# IVA2_CM register map
Vendor: Texas Instruments
Peripheral module from a debugger description file (folder omap34xx).
Registers are 32-bit, access per field, reset 0x0 unless marked. A register's access mark holds for its fields unless they carry their own. Offsets are as the file gives them; lines under a group give offsets from that group; [hi:lo] are bit positions; {n}, {i} and the like mark numbered series; 'fields as' and 'values as' point back to an identical list; <NAME> marks a mode.

## IVA2_CM
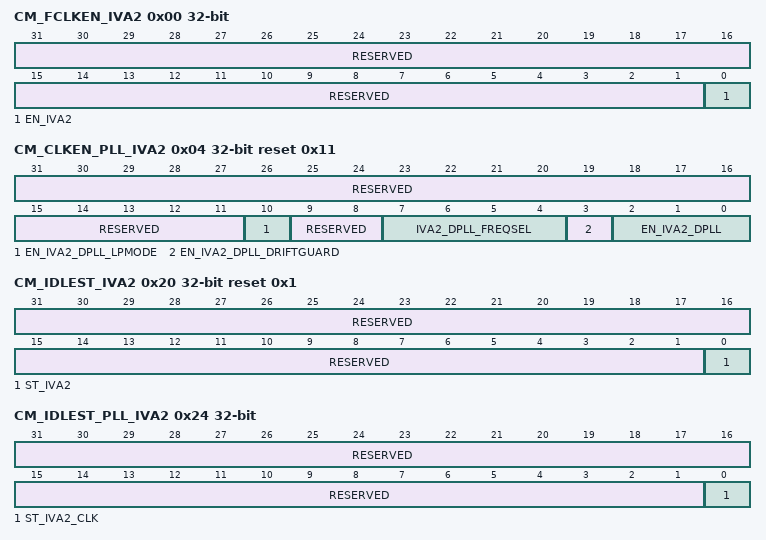
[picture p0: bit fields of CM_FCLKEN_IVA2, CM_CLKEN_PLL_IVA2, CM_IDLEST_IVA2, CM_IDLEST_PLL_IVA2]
0x00 CM_FCLKEN_IVA2 — This register controls the IVA2 domain functional clock activity.
  [31:1] RESERVED ro — Write 0s for future compatibility. Read returns 0.
  [0] EN_IVA2 rw — IVA2 functional clock control
    0=IVA2_CLK is disabled; 1=IVA2_CLK is enabled
0x04 CM_CLKEN_PLL_IVA2 reset 0x11 — This register controls the IVA2 DPLL modes.
  [31:11] RESERVED ro — Write 0s for future compatibility. Read returns 0.
  [10] EN_IVA2_DPLL_LPMODE rw — This bit allows to enable or disable the LP mode of the IVA2 DPLL. Writting this bit to switch the mode between LP or normal mode will take effect only when the DPLL will have transition into the bypass or stop state, followed by a lock or re-lock of the DPLL.
    0=Disables the DPLL LP mode to re-enter the normal mode at the following lock or re-lock sequence; 1=Enables the DPLL LP mode to enter the LP mode at the following lock or re-lock sequence
  [9:8] RESERVED rw — Write 0s for future compatibility. Read returns 0.
  [7:4] IVA2_DPLL_FREQSEL rw — This bit field allows selecting the proper range of the IVA2 DPLL internal frequency depending on the DPLL reference clock and the N divider.
    3=0.75 MHz 1.0 MHz0x4: 1.0 MHz 1.25 MHz 0x5: 1.25 MHz 1.5 MHz 0x6: 1.5 MHz 1.75 MHz 0x7: 1.75 MHz 2.1 MHz 0xB: 7.5 MHz 10 MHz 0xC: 10 MHz 12.5 MHz 0xD: 12.5 MHz 15 MHz 0xE: 15 MHz 17.5 MHz 0xF: 17.5 MHz 21 MHz
  [3] EN_IVA2_DPLL_DRIFTGUARD rw — This bit allows to enable or disable the automatic recalibration feature of the IVA2 DPLL. The IVA2 DPLL will automatically start a recalibration process upon assertion of the recal flag if this bit is set.
    0=Disables the IVA2 DPLL automatic recalibration mode; 1=Enables the IVA2 DPLL automatic recalibration mode
  [2:0] EN_IVA2_DPLL rw — IVA2 DPLL control; Other enums: Reserved
    1=Put the IVA2 DPLL in low power stop mode; 5=Put the IVA2 DPLL in low power bypass mode; 7=Enables the IVA2 DPLL in lock mode
0x20 CM_IDLEST_IVA2 ro reset 0x1 — IVA2 standby status and access availability monitoring. This register is read only and automatically updated.
  [31:1] RESERVED — Read returns 0.
  [0] ST_IVA2 — IVA2 standby status.
    0=IVA2 sub-system is active; 1=IVA2 sub-system is in standby mode
0x24 CM_IDLEST_PLL_IVA2 ro — This register allows monitoring the master clock activity. This register is read only and automatically updated.
  [31:1] RESERVED — Read returns 0.
  [0] ST_IVA2_CLK — IVA2_CLK activity
    0=IVA2 DPLL is bypassed; 1=IVA2 DPLL is locked
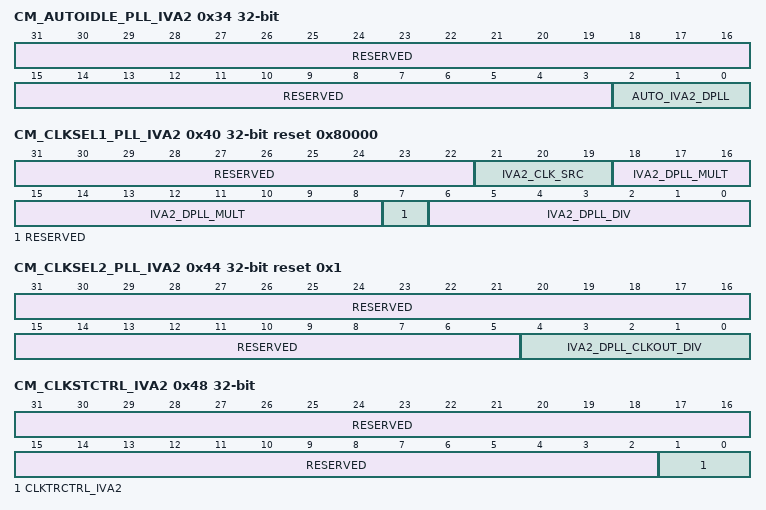
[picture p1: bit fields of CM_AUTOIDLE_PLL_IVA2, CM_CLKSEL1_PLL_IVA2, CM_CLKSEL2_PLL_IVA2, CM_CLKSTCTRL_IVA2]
0x34 CM_AUTOIDLE_PLL_IVA2 — This register provides automatic control over the IVA2 DPLL activity.
  [31:3] RESERVED ro — Write 0s for future compatibility. Read returns 0.
  [2:0] AUTO_IVA2_DPLL rw — IVA2 DPLL automatic control; Other enums: Reserved
    0=Auto control disabled; 1=IVA2 DPLL is automatically put in low power stop mode when the IVA2 clock is not required anymore. It is also restarted automatically.
0x40 CM_CLKSEL1_PLL_IVA2 reset 0x80000 — This register provides controls over the IVA2 DPLL.
  [31:22] RESERVED ro — Write 0s for future compatibility. Read returns 0.
  [21:19] IVA2_CLK_SRC rw — Selects the IVA2 DPLL bypass source clock; Other enums: Reserved
    1=DPLL2_FCLK is CORE_CLK divided by 1; 2=DPLL2_FCLK is CORE.CLK divided by 2; 4=DPLL2_FCLK is CORE.CLK divided by 4
  [18:8] IVA2_DPLL_MULT rw — IVA2 DPLL multiplier factor (0 to 2047)
  [7] RESERVED ro — Write 0s for future compatibility. Read returns 0.
  [6:0] IVA2_DPLL_DIV rw — IVA2 DPLL divider factor (0 to 127)
0x44 CM_CLKSEL2_PLL_IVA2 reset 0x1 — This register provides controls over the IVA2 DPLL.
  [31:5] RESERVED ro — Write 0s for future compatibility. Read returns 0.
  [4:0] IVA2_DPLL_CLKOUT_DIV rw — IVA2 DPLL output clock divider factor (1 up to 16); Other enums: Reserved
    {v}=DPLL2 CLKOUTX2 divided by {v} (v=1..9); 10=DPLL2 CLKOUTX2 is divided by 10; {v}=DPLL2 CLKOUTX2 divided by {v} (v=11..16)
0x48 CM_CLKSTCTRL_IVA2 — This register enables the domain power state transition. It controls the HW supervised domain power state transition between ACTIVE and INACTIVE states.
  [31:2] RESERVED ro — Write 0s for future compatibility. Read returns 0.
  [1:0] CLKTRCTRL_IVA2 rw — Controls the clock state transition of the IVA2 clock domain.
    0=Automatic transition is disabled; 1=Start a software supervised sleep transition on the domain; 2=Start a software supervised wake-up transition on the domain; 3=Automatic transition is enabled. Transition is supervised by the HardWare.
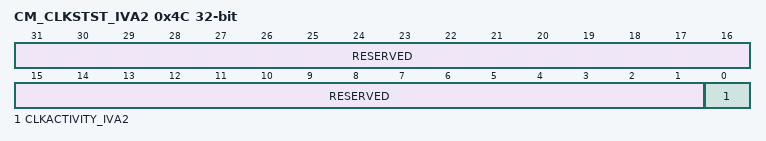
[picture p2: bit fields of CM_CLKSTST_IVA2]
0x4C CM_CLKSTST_IVA2 ro — This register provides a status on the clock activity in the domain (IVA2 DPLL output clock).
  [31:1] RESERVED — Write 0s for future compatibility. Read returns 0.
  [0] CLKACTIVITY_IVA2 — Clock activity status
    0=No domain clock activity; 1=Domain clock is active
